# STM32H747ZIY6@M7 register map
File version: 1.0
Registers are 32-bit, access not given, reset 0x0 unless marked. A register's access mark holds for its fields unless they carry their own. Offsets are from the block's base; [hi:lo] are bit positions; {n}, {i} and the like mark numbered series.

## DCMI
Base 0x48020000
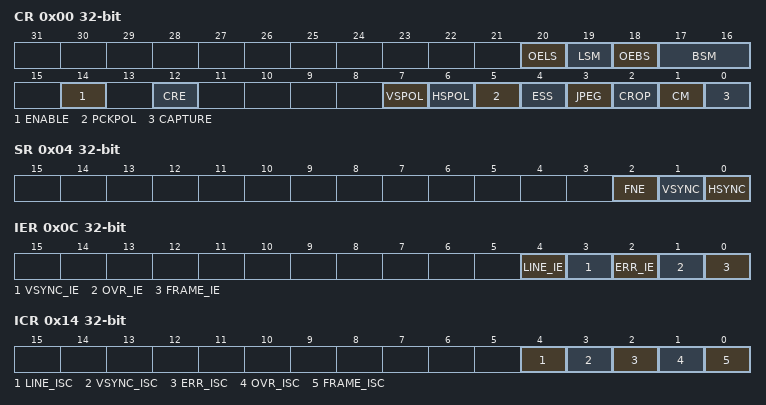
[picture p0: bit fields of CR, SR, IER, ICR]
0x00 CR
  [20] OELS, [19] LSM, [18] OEBS, [17:16] BSM, [14] ENABLE, [12] CRE, [7] VSPOL, [6] HSPOL, [5] PCKPOL, [4] ESS, [3] JPEG, [2] CROP, [1] CM, [0] CAPTURE
0x04 SR
  [2] FNE, [1] VSYNC, [0] HSYNC
0x08 RISR
0x0C IER
  [4] LINE_IE, [3] VSYNC_IE, [2] ERR_IE, [1] OVR_IE, [0] FRAME_IE
0x10 MISR
0x14 ICR
  [4] LINE_ISC, [3] VSYNC_ISC, [2] ERR_ISC, [1] OVR_ISC, [0] FRAME_ISC
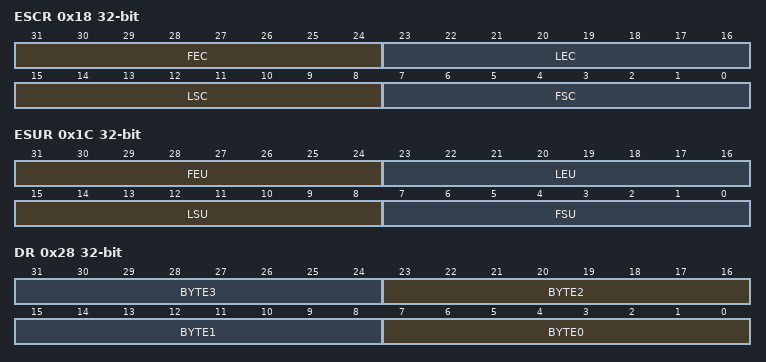
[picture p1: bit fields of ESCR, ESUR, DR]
0x18 ESCR
  [31:24] FEC, [23:16] LEC, [15:8] LSC, [7:0] FSC
0x1C ESUR
  [31:24] FEU, [23:16] LEU, [15:8] LSU, [7:0] FSU
0x20 CWSTRTR
0x24 CWSIZER
0x28 DR
  [8n+7:8n] BYTE{n} (n=0..3)

## RNG
Base 0x48021800
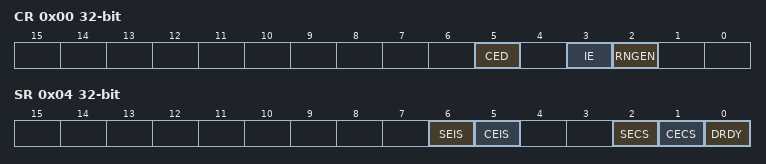
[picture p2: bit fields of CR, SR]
0x00 CR
  [5] CED, [3] IE, [2] RNGEN
0x04 SR
  [6] SEIS, [5] CEIS, [2] SECS, [1] CECS, [0] DRDY
0x08 DR

## SDMMC2
Base 0x48022400
Same registers: SDMMC1 0x52007000
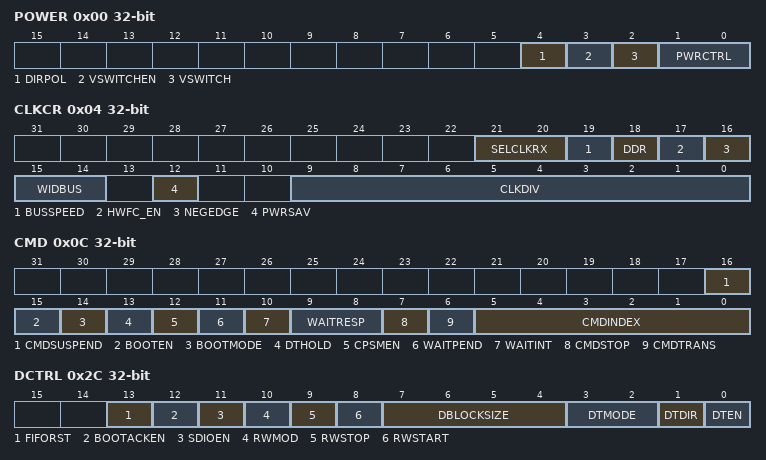
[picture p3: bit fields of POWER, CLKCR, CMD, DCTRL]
0x00 POWER
  [4] DIRPOL, [3] VSWITCHEN, [2] VSWITCH, [1:0] PWRCTRL
0x04 CLKCR
  [21:20] SELCLKRX, [19] BUSSPEED, [18] DDR, [17] HWFC_EN, [16] NEGEDGE, [15:14] WIDBUS, [12] PWRSAV, [9:0] CLKDIV
0x08 ARG
  [31:0] CMDARG
0x0C CMD
  [16] CMDSUSPEND, [15] BOOTEN, [14] BOOTMODE, [13] DTHOLD, [12] CPSMEN, [11] WAITPEND, [10] WAITINT, [9:8] WAITRESP, [7] CMDSTOP, [6] CMDTRANS, [5:0] CMDINDEX
0x10 RESPCMD
  [5:0] RESPCMD
{0x10+4i} RESP{i} (i=1..4)
  [31:0] CARDSTATUS{i}
0x24 DTIMER
  [31:0] DATATIME
0x28 DLEN
  [24:0] DATALENGTH
0x2C DCTRL
  [13] FIFORST, [12] BOOTACKEN, [11] SDIOEN, [10] RWMOD, [9] RWSTOP, [8] RWSTART, [7:4] DBLOCKSIZE, [3:2] DTMODE, [1] DTDIR, [0] DTEN
0x30 DCOUNT
  [24:0] DATACOUNT
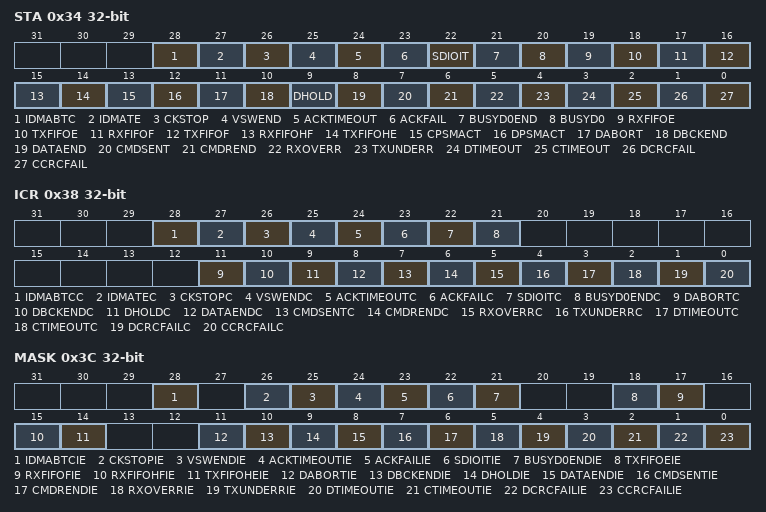
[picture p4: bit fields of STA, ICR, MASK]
0x34 STA
  [28] IDMABTC, [27] IDMATE, [26] CKSTOP, [25] VSWEND, [24] ACKTIMEOUT, [23] ACKFAIL, [22] SDIOIT, [21] BUSYD0END, [20] BUSYD0, [19] RXFIFOE, [18] TXFIFOE, [17] RXFIFOF, [16] TXFIFOF, [15] RXFIFOHF, [14] TXFIFOHE, [13] CPSMACT, [12] DPSMACT, [11] DABORT, [10] DBCKEND, [9] DHOLD, [8] DATAEND, [7] CMDSENT, [6] CMDREND, [5] RXOVERR, [4] TXUNDERR, [3] DTIMEOUT, [2] CTIMEOUT, [1] DCRCFAIL, [0] CCRCFAIL
0x38 ICR
  [28] IDMABTCC, [27] IDMATEC, [26] CKSTOPC, [25] VSWENDC, [24] ACKTIMEOUTC, [23] ACKFAILC, [22] SDIOITC, [21] BUSYD0ENDC, [11] DABORTC, [10] DBCKENDC, [9] DHOLDC, [8] DATAENDC, [7] CMDSENTC, [6] CMDRENDC, [5] RXOVERRC, [4] TXUNDERRC, [3] DTIMEOUTC, [2] CTIMEOUTC, [1] DCRCFAILC, [0] CCRCFAILC
0x3C MASK
  [28] IDMABTCIE, [26] CKSTOPIE, [25] VSWENDIE, [24] ACKTIMEOUTIE, [23] ACKFAILIE, [22] SDIOITIE, [21] BUSYD0ENDIE, [18] TXFIFOEIE, [17] RXFIFOFIE, [15] RXFIFOHFIE, [14] TXFIFOHEIE, [11] DABORTIE, [10] DBCKENDIE, [9] DHOLDIE, [8] DATAENDIE, [7] CMDSENTIE, [6] CMDRENDIE, [5] RXOVERRIE, [4] TXUNDERRIE, [3] DTIMEOUTIE, [2] CTIMEOUTIE, [1] DCRCFAILIE, [0] CCRCFAILIE
0x40 ACKTIME
  [24:0] ACKTIME
0x50 IDMACTRL
0x54 IDMABSIZE
  [12:5] IDMABNDT
0x58 IDMABASE0
0x5C IDMABASE1
0x80 FIFO
  [31:0] FIFODATA
0x3FC IPVR

## DLYB_SDMMC2
Base 0x48022800
Same registers: DLYB_QUADSPI 0x52006000, DLYB_SDMMC1 0x52008000
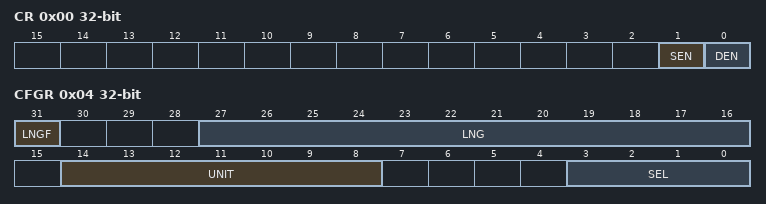
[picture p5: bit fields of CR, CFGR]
0x00 CR
  [1] SEN, [0] DEN
0x04 CFGR
  [31] LNGF, [27:16] LNG, [14:8] UNIT, [3:0] SEL

## RAMECC2
Base 0x48023000
Same registers: RAMECC1 0x52009000, RAMECC3 0x58027000
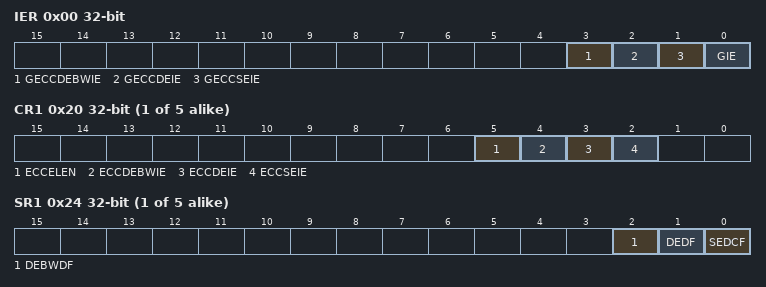
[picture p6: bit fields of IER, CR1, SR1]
0x00 IER
  [3] GECCDEBWIE, [2] GECCDEIE, [1] GECCSEIE, [0] GIE
{0x0+0x20*i} CR{i} (i=1..5)
  [5] ECCELEN, [4] ECCDEBWIE, [3] ECCDEIE, [2] ECCSEIE
{0x4+0x20*i} SR{i} (i=1..5)
  [2] DEBWDF, [1] DEDF, [0] SEDCF
{0x8+0x20*i} FAR{i} (i=1..5)
  [31:0] FDATAL
{0xC+0x20*i} FDRL{i} (i=1..5)
{0x10+0x20*i} FDRH{i} (i=1..5)
{0x14+0x20*i} FECR{i} (i=1..5)
  [31:0] FEC

## LTDC
Base 0x50001000
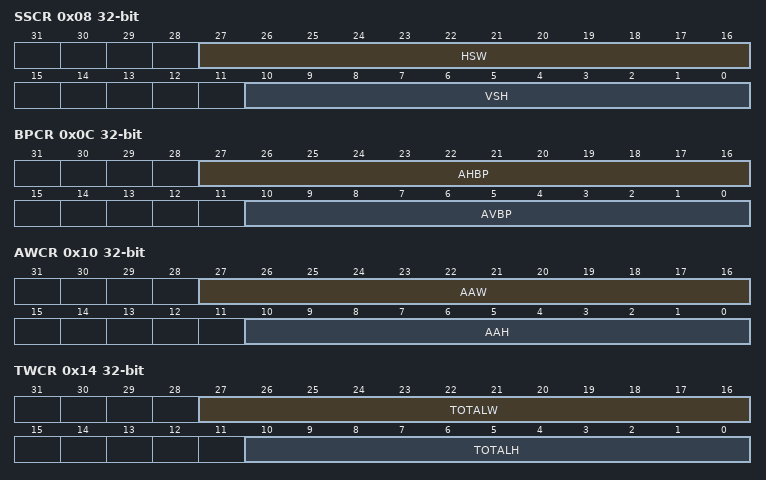
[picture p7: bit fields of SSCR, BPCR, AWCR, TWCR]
0x08 SSCR
  [27:16] HSW, [10:0] VSH
0x0C BPCR
  [27:16] AHBP, [10:0] AVBP
0x10 AWCR
  [27:16] AAW, [10:0] AAH
0x14 TWCR
  [27:16] TOTALW, [10:0] TOTALH
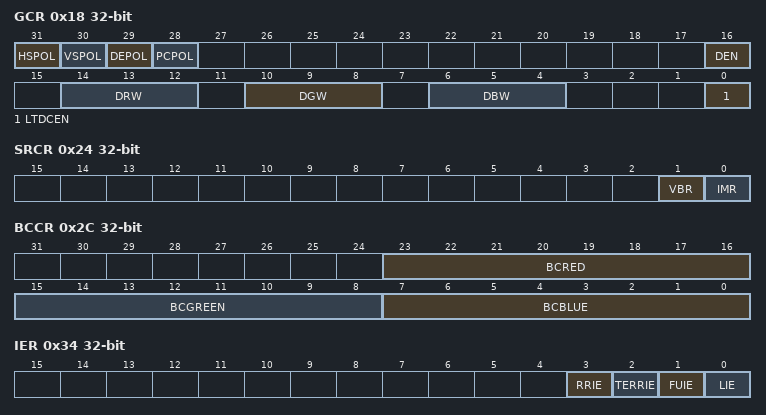
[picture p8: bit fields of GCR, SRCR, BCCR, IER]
0x18 GCR
  [31] HSPOL, [30] VSPOL, [29] DEPOL, [28] PCPOL, [16] DEN, [14:12] DRW, [10:8] DGW, [6:4] DBW, [0] LTDCEN
0x24 SRCR
  [1] VBR, [0] IMR
0x2C BCCR
  [23:16] BCRED, [15:8] BCGREEN, [7:0] BCBLUE
0x34 IER
  [3] RRIE, [2] TERRIE, [1] FUIE, [0] LIE
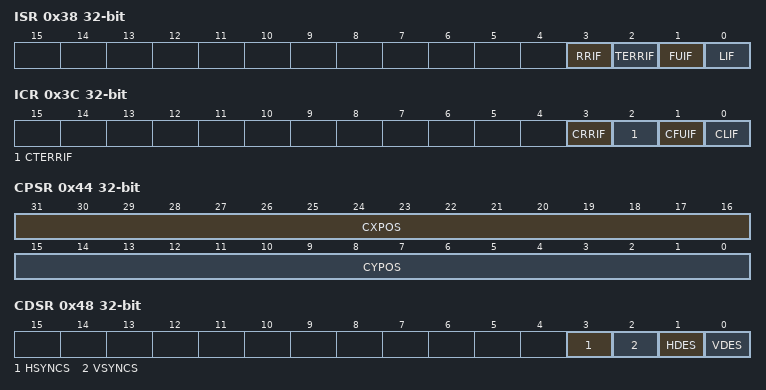
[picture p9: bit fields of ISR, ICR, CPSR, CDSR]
0x38 ISR
  [3] RRIF, [2] TERRIF, [1] FUIF, [0] LIF
0x3C ICR
  [3] CRRIF, [2] CTERRIF, [1] CFUIF, [0] CLIF
0x40 LIPCR
  [10:0] LIPOS
0x44 CPSR
  [31:16] CXPOS, [15:0] CYPOS
0x48 CDSR
  [3] HSYNCS, [2] VSYNCS, [1] HDES, [0] VDES
0x84 CR1
0x88 WHPCR1
0x8C WVPCR1
0x90 CKCR1
0x94 PFCR1
0x98 CACR1
0x9C DCCR1
0xA0 BFCR1
0xAC CFBAR1
0xB0 CFBLR1
0xB4 CFBLNR1
0xC4 CLUTWR1
0x104 CR2
0x108 WHPCR2
0x10C WVPCR2
0x110 CKCR2
0x114 PFCR2
0x118 CACR2
0x11C DCCR2
0x120 BFCR2
0x12C CFBAR2
0x130 CFBLR2
0x134 CFBLNR2
0x144 CLUTWR2
